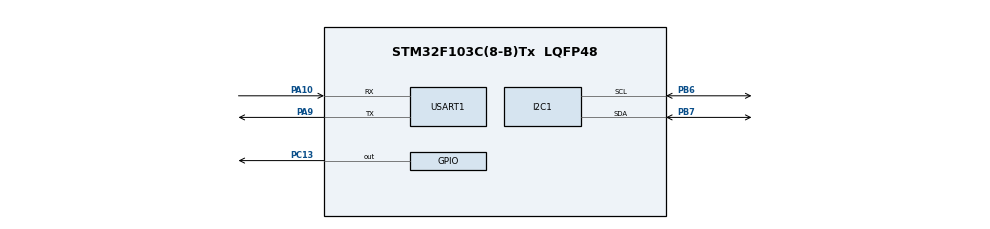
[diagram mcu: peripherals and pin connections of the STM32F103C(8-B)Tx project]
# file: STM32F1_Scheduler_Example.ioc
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Mcu.Family=STM32F1
Mcu.Name=STM32F103C(8-B)Tx
Mcu.Package=LQFP48
NVIC.PriorityGroup=NVIC_PRIORITYGROUP_4
PA10.Mode=Asynchronous
PA10.Signal=USART1_RX
PA13.Mode=Serial_Wire
PA13.Signal=SYS_JTMS-SWDIO
PA14.Mode=Serial_Wire
PA14.Signal=SYS_JTCK-SWCLK
PA9.Mode=Asynchronous
PA9.Signal=USART1_TX
PB6.Mode=I2C
PB6.Signal=I2C1_SCL
PB7.Mode=I2C
PB7.Signal=I2C1_SDA
PC13-TAMPER-RTC.Signal=GPIO_Output
PD0-OSC_IN.Mode=HSE-External-Oscillator
PD0-OSC_IN.Signal=RCC_OSC_IN
PD1-OSC_OUT.Mode=HSE-External-Oscillator
PD1-OSC_OUT.Signal=RCC_OSC_OUT
ProjectManager.HeapSize=0x200
ProjectManager.StackSize=0x400
ProjectManager.TargetToolchain=STM32CubeIDE
RCC.APB1Freq_Value=8000000
RCC.APB2Freq_Value=8000000
RCC.PLLSourceVirtual=RCC_PLLSOURCE_HSE
RCC.USBFreq_Value=16000000
USART1.VirtualMode=VM_ASYNC
board=custom

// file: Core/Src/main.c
/* USER CODE BEGIN Header */
/**
  ******************************************************************************
  * @file           : main.c
  * @brief          : Main program body
  ******************************************************************************
  * @attention
  *
  * Copyright (c) 2024 STMicroelectronics.
  * All rights reserved.
  *
  * This software is licensed under terms that can be found in the LICENSE file
  * in the root directory of this software component.
  * If no LICENSE file comes with this software, it is provided AS-IS.
  *
  ******************************************************************************
  */
/* USER CODE END Header */
#include "main.h"

/* USER CODE BEGIN Includes */
#include "scheduler.h"
/* USER CODE END Includes */

void SystemClock_Config(void);
static void MX_GPIO_Init(void);
static void MX_I2C1_Init(void);
static void MX_USART1_UART_Init(void);

int main(void)
{

  /* MCU Configuration--------------------------------------------------------*/

  /* Reset of all peripherals, Initializes the Flash interface and the Systick. */
  LL_APB2_GRP1_EnableClock(LL_APB2_GRP1_PERIPH_AFIO);
  LL_APB1_GRP1_EnableClock(LL_APB1_GRP1_PERIPH_PWR);

  /* System interrupt init*/
  NVIC_SetPriorityGrouping(NVIC_PRIORITYGROUP_4);

  /* SysTick_IRQn interrupt configuration */
  NVIC_SetPriority(SysTick_IRQn, NVIC_EncodePriority(NVIC_GetPriorityGrouping(),15, 0));

  /** NOJTAG: JTAG-DP Disabled and SW-DP Enabled
  */
  LL_GPIO_AF_Remap_SWJ_NOJTAG();

  /* Configure the system clock */
  SystemClock_Config();

  /* Initialize all configured peripherals */
  MX_GPIO_Init();
  MX_I2C1_Init();
  MX_USART1_UART_Init();

  /* Infinite loop */
  while (1)
  {

  }
}

void SystemClock_Config(void)
{
  LL_FLASH_SetLatency(LL_FLASH_LATENCY_0);
  while(LL_FLASH_GetLatency()!= LL_FLASH_LATENCY_0)
  {
  }
  LL_RCC_HSI_SetCalibTrimming(16);
  LL_RCC_HSI_Enable();

   /* Wait till HSI is ready */
  while(LL_RCC_HSI_IsReady() != 1)
  {

  }
  LL_RCC_SetAHBPrescaler(LL_RCC_SYSCLK_DIV_1);
  LL_RCC_SetAPB1Prescaler(LL_RCC_APB1_DIV_1);
  LL_RCC_SetAPB2Prescaler(LL_RCC_APB2_DIV_1);
  LL_RCC_SetSysClkSource(LL_RCC_SYS_CLKSOURCE_HSI);

   /* Wait till System clock is ready */
  while(LL_RCC_GetSysClkSource() != LL_RCC_SYS_CLKSOURCE_STATUS_HSI)
  {

  }
  LL_Init1msTick(8000000);
  LL_SetSystemCoreClock(8000000);
}

static void MX_I2C1_Init(void)
{

  LL_I2C_InitTypeDef I2C_InitStruct = {0};

  LL_GPIO_InitTypeDef GPIO_InitStruct = {0};

  LL_APB2_GRP1_EnableClock(LL_APB2_GRP1_PERIPH_GPIOB);
  /**I2C1 GPIO Configuration
  PB6   ------> I2C1_SCL
  PB7   ------> I2C1_SDA
  */
  GPIO_InitStruct.Pin = LL_GPIO_PIN_6|LL_GPIO_PIN_7;
  GPIO_InitStruct.Mode = LL_GPIO_MODE_ALTERNATE;
  GPIO_InitStruct.Speed = LL_GPIO_SPEED_FREQ_HIGH;
  GPIO_InitStruct.OutputType = LL_GPIO_OUTPUT_OPENDRAIN;
  LL_GPIO_Init(GPIOB, &GPIO_InitStruct);

  /* Peripheral clock enable */
  LL_APB1_GRP1_EnableClock(LL_APB1_GRP1_PERIPH_I2C1);

  /** I2C Initialization
  */
  LL_I2C_DisableOwnAddress2(I2C1);
  LL_I2C_DisableGeneralCall(I2C1);
  LL_I2C_EnableClockStretching(I2C1);
  I2C_InitStruct.PeripheralMode = LL_I2C_MODE_I2C;
  I2C_InitStruct.ClockSpeed = 100000;
  I2C_InitStruct.DutyCycle = LL_I2C_DUTYCYCLE_2;
  I2C_InitStruct.OwnAddress1 = 0;
  I2C_InitStruct.TypeAcknowledge = LL_I2C_ACK;
  I2C_InitStruct.OwnAddrSize = LL_I2C_OWNADDRESS1_7BIT;
  LL_I2C_Init(I2C1, &I2C_InitStruct);
  LL_I2C_SetOwnAddress2(I2C1, 0);

}

static void MX_USART1_UART_Init(void)
{

  LL_USART_InitTypeDef USART_InitStruct = {0};

  LL_GPIO_InitTypeDef GPIO_InitStruct = {0};

  /* Peripheral clock enable */
  LL_APB2_GRP1_EnableClock(LL_APB2_GRP1_PERIPH_USART1);

  LL_APB2_GRP1_EnableClock(LL_APB2_GRP1_PERIPH_GPIOA);
  /**USART1 GPIO Configuration
  PA9   ------> USART1_TX
  PA10   ------> USART1_RX
  */
  GPIO_InitStruct.Pin = LL_GPIO_PIN_9;
  GPIO_InitStruct.Mode = LL_GPIO_MODE_ALTERNATE;
  GPIO_InitStruct.Speed = LL_GPIO_SPEED_FREQ_HIGH;
  GPIO_InitStruct.OutputType = LL_GPIO_OUTPUT_PUSHPULL;
  LL_GPIO_Init(GPIOA, &GPIO_InitStruct);

  GPIO_InitStruct.Pin = LL_GPIO_PIN_10;
  GPIO_InitStruct.Mode = LL_GPIO_MODE_FLOATING;
  LL_GPIO_Init(GPIOA, &GPIO_InitStruct);

  USART_InitStruct.BaudRate = 115200;
  USART_InitStruct.DataWidth = LL_USART_DATAWIDTH_8B;
  USART_InitStruct.StopBits = LL_USART_STOPBITS_1;
  USART_InitStruct.Parity = LL_USART_PARITY_NONE;
  USART_InitStruct.TransferDirection = LL_USART_DIRECTION_TX_RX;
  USART_InitStruct.HardwareFlowControl = LL_USART_HWCONTROL_NONE;
  USART_InitStruct.OverSampling = LL_USART_OVERSAMPLING_16;
  LL_USART_Init(USART1, &USART_InitStruct);
  LL_USART_ConfigAsyncMode(USART1);
  LL_USART_Enable(USART1);

}

static void MX_GPIO_Init(void)
{
  LL_GPIO_InitTypeDef GPIO_InitStruct = {0};

  /* GPIO Ports Clock Enable */
  LL_APB2_GRP1_EnableClock(LL_APB2_GRP1_PERIPH_GPIOC);
  LL_APB2_GRP1_EnableClock(LL_APB2_GRP1_PERIPH_GPIOD);
  LL_APB2_GRP1_EnableClock(LL_APB2_GRP1_PERIPH_GPIOA);
  LL_APB2_GRP1_EnableClock(LL_APB2_GRP1_PERIPH_GPIOB);

  /**/
  LL_GPIO_ResetOutputPin(GPIOC, LL_GPIO_PIN_13);

  /**/
  GPIO_InitStruct.Pin = LL_GPIO_PIN_13;
  GPIO_InitStruct.Mode = LL_GPIO_MODE_OUTPUT;
  GPIO_InitStruct.Speed = LL_GPIO_SPEED_FREQ_LOW;
  GPIO_InitStruct.OutputType = LL_GPIO_OUTPUT_PUSHPULL;
  LL_GPIO_Init(GPIOC, &GPIO_InitStruct);

}

void Error_Handler(void)
{
  __disable_irq();
  while (1)
  {
  }
}
